# ATmega3209 device description
Architecture: AVR8X; Family: AVR MEGA
Registers are 8-bit, read-write, no defined reset value unless marked. A register's access mark holds for its fields unless they carry their own. Offsets are from the block's base; [hi:lo] are bit positions; {n}, {i} and the like mark numbered series.

## BOD — Bod interface
Instances: BOD 0x0080
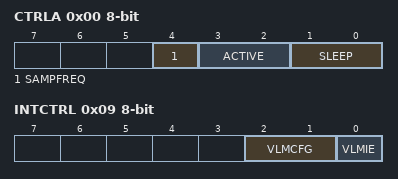
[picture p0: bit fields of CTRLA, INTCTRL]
0x00 CTRLA — Control A
  [4] SAMPFREQ ro — Sample frequency
    0=1KHZ (1kHz sampling frequency); 1=125HZ (125kHz sampling frequency)
  [3:2] ACTIVE ro — Operation in active mode
    0=DIS (Disabled); 1=ENABLED; 2=SAMPLED; 3=ENWAKE (Enabled with wake-up halted until BOD is ready)
  [1:0] SLEEP — Operation in sleep mode
    0=DIS (Disabled); 1=ENABLED; 2=SAMPLED
0x01 CTRLB — Control B
  [2:0] LVL ro — Bod level
    0=BODLEVEL0 (1.8 V); 1=BODLEVEL1 (2.1 V); 2=BODLEVEL2 (2.6 V); 3=BODLEVEL3 (2.9 V); 4=BODLEVEL4 (3.3 V); 5=BODLEVEL5 (3.7 V); 6=BODLEVEL6 (4.0 V); 7=BODLEVEL7 (4.2 V)
0x08 VLMCTRLA — Voltage level monitor Control
  [1:0] VLMLVL — voltage level monitor level
    0=5ABOVE (VLM threshold 5% above BOD level); 1=15ABOVE (VLM threshold 15% above BOD level); 2=25ABOVE (VLM threshold 25% above BOD level)
0x09 INTCTRL — Voltage level monitor interrupt Control
  [2:1] VLMCFG — Configuration
    0=BELOW (Interrupt when supply goes below VLM level); 1=ABOVE (Interrupt when supply goes above VLM level); 2=CROSS (Interrupt when supply crosses VLM level)
  [0] VLMIE — voltage level monitor interrrupt enable
0x0A INTFLAGS — Voltage level monitor interrupt Flags
  [0] VLMIF — Voltage level monitor interrupt flag
0x0B STATUS — Voltage level monitor status
  [0] VLMS ro

## CCL — Configurable Custom Logic
Instances: CCL 0x01C0
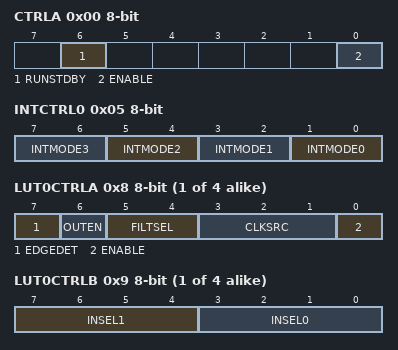
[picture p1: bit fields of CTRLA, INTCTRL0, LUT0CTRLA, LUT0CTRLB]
0x00 CTRLA — Control Register A
  [6] RUNSTDBY — Run in Standby
  [0] ENABLE
0x01 SEQCTRL0 — Sequential Control 0
  [2:0] SEQSEL — Sequential Selection
    0=DISABLE (Sequential logic disabled); 1=DFF (D FlipFlop); 2=JK (JK FlipFlop); 3=LATCH (D Latch); 4=RS (RS Latch)
0x05 INTCTRL0 — Interrupt Control 0
  [all] fields
    0=BOTH (Sense both edges); 1=FALLING (Sense falling edge); 2=RISING (Sense rising edge); 3=INTDISABLE (Interrupt disabled)
  [2n+1:2n] INTMODE{n} (n=0..3) — Interrupt Mode for LUT{n}
0x07 INTFLAGS — Interrupt Flags
  [3:0] INT
{0x8+4i} LUT{i}CTRLA (i=0..3) — LUT Control {i} A
  [7] EDGEDET — Edge Detection Enable
    0=DIS (Edge detector is disabled); 1=EN (Edge detector is enabled)
  [6] OUTEN — Output Enable
  [5:4] FILTSEL — Filter Selection
    0=DISABLE (Filter disabled); 1=SYNCH (Synchronizer enabled); 2=FILTER (Filter enabled)
  [3:1] CLKSRC — Clock Source Selection
    0=CLKPER (CLK_PER is clocking the LUT); 1=IN2 (IN[2] is clocking the LUT); 2=OSC20M (20MHz oscillator before prescaler is clocking the LUT); 3=OSCULP32K (32kHz oscillator is clocking the LUT); 4=OSCULP1K (32kHz oscillator after DIV32 is clocking the LUT)
  [0] ENABLE — LUT Enable
{0x9+4i} LUT{i}CTRLB (i=0..3) — LUT Control {i} B
  [7:4] INSEL1 — LUT Input 1 Source Selection
    0=MASK (Masked input); 1=FEEDBACK (Feedback input source); 2=LINK (Linked LUT input source); 3=EVENTA (Event input source A); 4=EVENTB (Event input source B); 5=IO (IO pin LUTn-N1 input source); 6=AC0 (AC0 OUT input source); 8=USART1 (USART1 TXD input source); 9=SPI0 (SPI0 MOSI input source); 10=TCA0 (TCA0 WO1 input source); 12=TCB1 (TCB1 WO input source); 13=TCD0 (TCD0 WOB input soruce)
  [3:0] INSEL0 — LUT Input 0 Source Selection
    0=MASK (Masked input); 1=FEEDBACK (Feedback input source); 2=LINK (Linked LUT input source); 3=EVENTA (Event input source A); 4=EVENTB (Event input source B); 5=IO (IO pin LUTn-IN0 input source); 6=AC0 (AC0 OUT input source); 8=USART0 (USART0 TXD input source); 9=SPI0 (SPI0 MOSI input source); 10=TCA0 (TCA0 WO0 input source); 12=TCB0 (TCB0 WO input source); 13=TCD0 (TCD0 WOA input source)
{0xA+4i} LUT{i}CTRLC (i=0..3) — LUT Control {i} C
  [3:0] INSEL2 — LUT Input 2 Source Selection
    0=MASK (Masked input); 1=FEEDBACK (Feedback input source); 2=LINK (Linked LUT input source); 3=EVENTA (Event input source A); 4=EVENTB (Event input source B); 5=IO (IO pin LUTn-IN2 input source); 6=AC0 (AC0 OUT input source); 8=USART2 (USART2 TXD input source); 9=SPI0 (SPI0 SCK input source); 10=TCA0 (TCA0 WO2 input source); 12=TCB2 (TCB2 WO input source); 13=TCD0 (TCD0 WOC input source)
{0xB+4i} TRUTH{i} (i=0..3)
